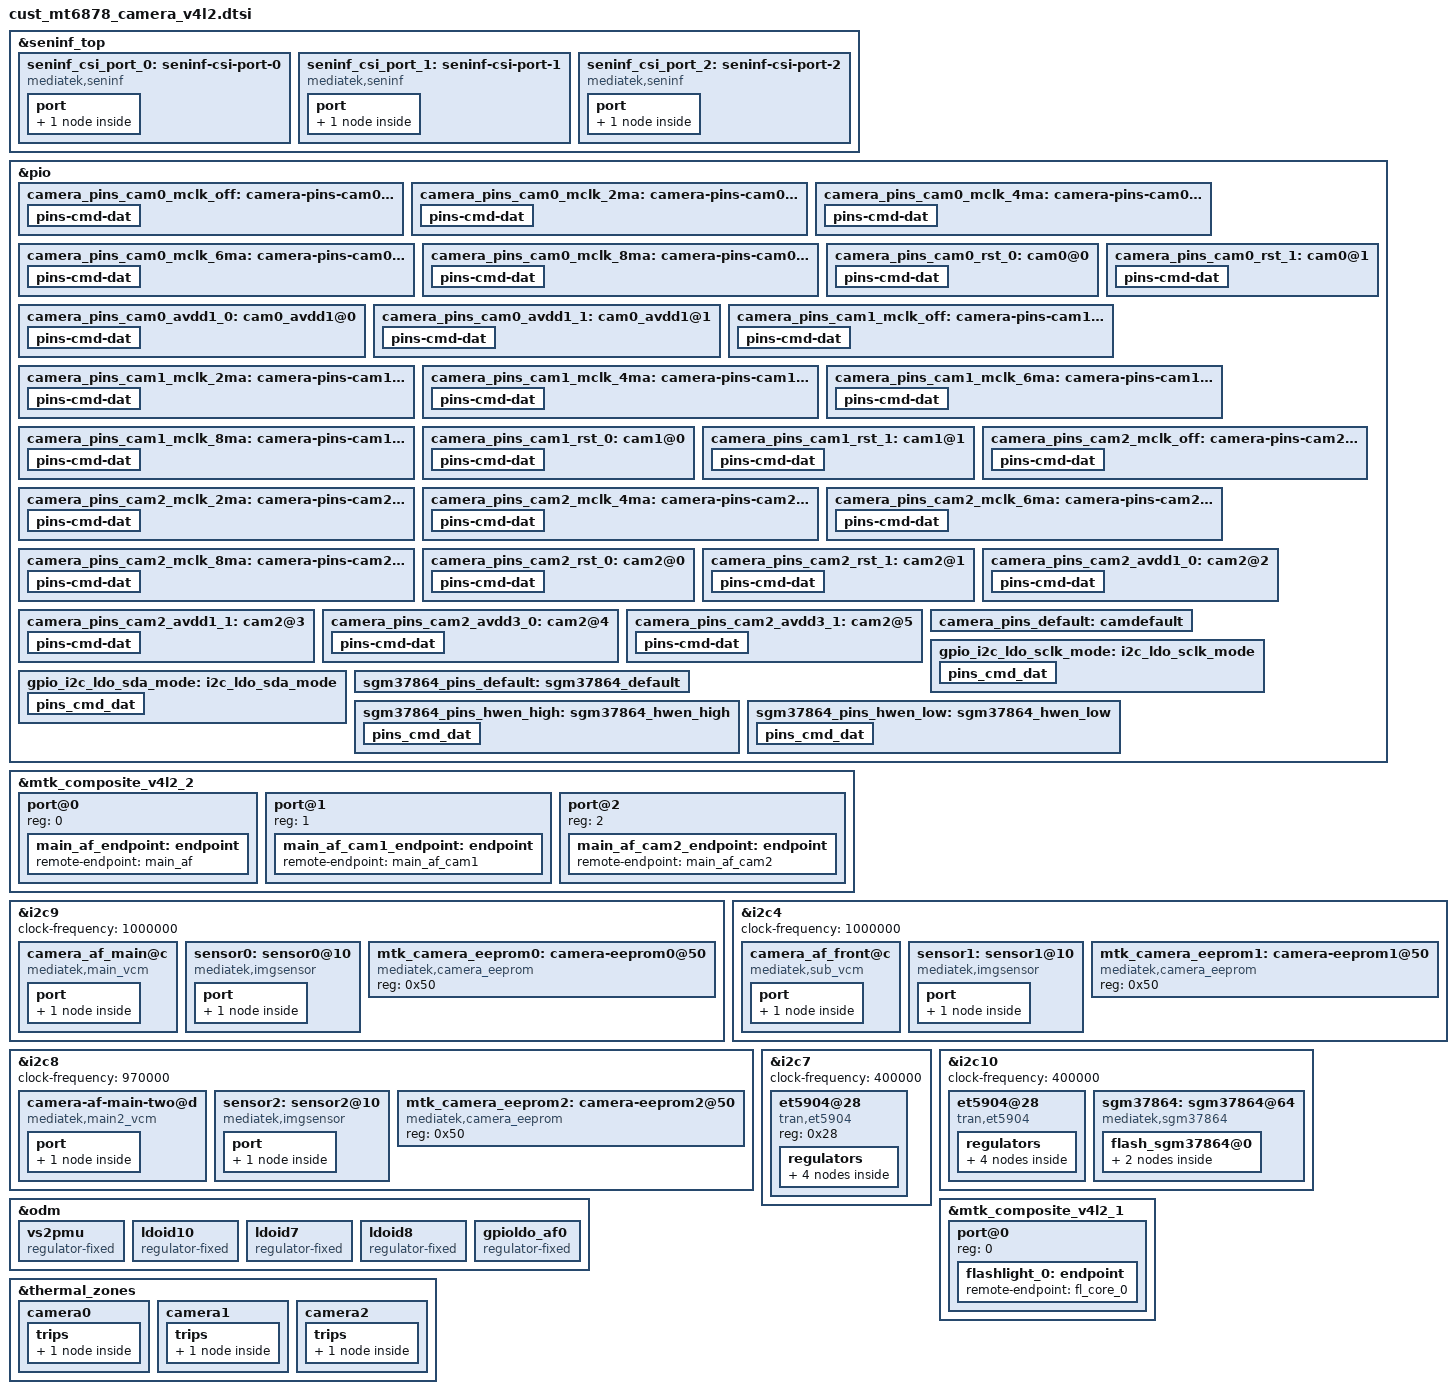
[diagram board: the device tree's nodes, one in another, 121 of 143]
// SPDX-License-Identifier: GPL-2.0
/* Copyright (c) 2020 MediaTek Inc. */
#include <dt-bindings/clock/mt6878-clk.h>

&seninf_top {
		seninf_csi_port_0: seninf-csi-port-0 {
			compatible = "mediatek,seninf";
			csi-port = "0";
			dphy-settle-delay-dt = <17>;
			nvmem-cells = <&csi_efuse0>;
			nvmem-cell-names = "rg_csi";
			port {
				seninf_csi_port_0_in: endpoint {
					remote-endpoint = <&sensor0_out>;
				};
			};
		};

		seninf_csi_port_1: seninf-csi-port-1 {
			compatible = "mediatek,seninf";
			csi-port = "1";
			hs-trail-parameter = <0x20>;
			nvmem-cells = <&csi_efuse1>;
			nvmem-cell-names = "rg_csi";
			port {
				seninf_csi_port_1_in: endpoint {
					remote-endpoint = <&sensor2_out>;
				};
			};
		};

		seninf_csi_port_2: seninf-csi-port-2 {
			compatible = "mediatek,seninf";
			csi-port = "2";
			hs-trail-parameter = <0x20>;
			nvmem-cells = <&csi_efuse2>;
			nvmem-cell-names = "rg_csi";
			port {
				seninf_csi_port_2_in: endpoint {
					remote-endpoint = <&sensor1_out>;
				};
			};
		};
};


/* CAMERA GPIO standardization */
&pio {
	camera_pins_cam0_mclk_off: camera-pins-cam0-mclk-off {
		pins-cmd-dat {
			pinmux = <PINMUX_GPIO93__FUNC_GPIO93>;
			drive-strength = <1>;
		};
	};
	camera_pins_cam0_mclk_2ma: camera-pins-cam0-mclk-2ma {
		pins-cmd-dat {
			pinmux = <PINMUX_GPIO93__FUNC_CMMCLK1>;
			drive-strength = <0>;
		};
	};
	camera_pins_cam0_mclk_4ma: camera-pins-cam0-mclk-4ma {
		pins-cmd-dat {
			pinmux = <PINMUX_GPIO93__FUNC_CMMCLK1>;
			drive-strength = <1>;
		};
	};
	camera_pins_cam0_mclk_6ma: camera-pins-cam0-mclk-6ma {
		pins-cmd-dat {
			pinmux = <PINMUX_GPIO93__FUNC_CMMCLK1>;
			drive-strength = <2>;
		};
	};
	camera_pins_cam0_mclk_8ma: camera-pins-cam0-mclk-8ma {
		pins-cmd-dat {
			pinmux = <PINMUX_GPIO93__FUNC_CMMCLK1>;
			drive-strength = <3>;
		};
	};
	camera_pins_cam0_rst_0: cam0@0 {
		pins-cmd-dat {
			pinmux = <PINMUX_GPIO25__FUNC_GPIO25>;
			slew-rate = <1>;
			output-low;
		};
	};
	camera_pins_cam0_rst_1: cam0@1 {
		pins-cmd-dat {
			pinmux = <PINMUX_GPIO25__FUNC_GPIO25>;
			slew-rate = <1>;
			output-high;
		};
	};

	camera_pins_cam0_avdd1_0: cam0_avdd1@0 {
		pins-cmd-dat {
			pinmux = <PINMUX_GPIO30__FUNC_GPIO30>;
			slew-rate = <1>;
			output-low;
		};
	};

	camera_pins_cam0_avdd1_1: cam0_avdd1@1 {
		pins-cmd-dat {
			pinmux = <PINMUX_GPIO30__FUNC_GPIO30>;
			slew-rate = <1>;
			output-high;
		};
	};

	camera_pins_cam1_mclk_off: camera-pins-cam1-mclk-off {
		pins-cmd-dat {
			pinmux = <PINMUX_GPIO96__FUNC_GPIO96>;
			drive-strength = <1>;
		};
	};
	camera_pins_cam1_mclk_2ma: camera-pins-cam1-mclk-2ma {
		pins-cmd-dat {
			pinmux = <PINMUX_GPIO96__FUNC_CMMCLK4>;
			drive-strength = <0>;
		};
	};
	camera_pins_cam1_mclk_4ma: camera-pins-cam1-mclk-4ma {
		pins-cmd-dat {
			pinmux = <PINMUX_GPIO96__FUNC_CMMCLK4>;
			drive-strength = <1>;
		};
	};
	camera_pins_cam1_mclk_6ma: camera-pins-cam1-mclk-6ma {
		pins-cmd-dat {
			pinmux = <PINMUX_GPIO96__FUNC_CMMCLK4>;
			drive-strength = <2>;
		};
	};
	camera_pins_cam1_mclk_8ma: camera-pins-cam1-mclk-8ma {
		pins-cmd-dat {
			pinmux = <PINMUX_GPIO96__FUNC_CMMCLK4>;
			drive-strength = <3>;
		};
	};
	camera_pins_cam1_rst_0: cam1@0 {
		pins-cmd-dat {
			pinmux = <PINMUX_GPIO24__FUNC_GPIO24>;
			slew-rate = <1>;
			output-low;
		};
	};
	camera_pins_cam1_rst_1: cam1@1 {
		pins-cmd-dat {
			pinmux = <PINMUX_GPIO24__FUNC_GPIO24>;
			slew-rate = <1>;
			output-high;
		};
	};
	camera_pins_cam2_mclk_off: camera-pins-cam2-mclk-off {
		pins-cmd-dat {
			pinmux = <PINMUX_GPIO94__FUNC_GPIO94>;
			drive-strength = <1>;
		};
	};
	camera_pins_cam2_mclk_2ma: camera-pins-cam2-mclk-2ma {
		pins-cmd-dat {
			pinmux = <PINMUX_GPIO94__FUNC_CMMCLK2>;
			drive-strength = <0>;
		};
	};
	camera_pins_cam2_mclk_4ma: camera-pins-cam2-mclk-4ma {
		pins-cmd-dat {
			pinmux = <PINMUX_GPIO94__FUNC_CMMCLK2>;
			drive-strength = <1>;
		};
	};
	camera_pins_cam2_mclk_6ma: camera-pins-cam2-mclk-6ma {
		pins-cmd-dat {
			pinmux = <PINMUX_GPIO94__FUNC_CMMCLK2>;
			drive-strength = <2>;
		};
	};
	camera_pins_cam2_mclk_8ma: camera-pins-cam2-mclk-8ma {
		pins-cmd-dat {
			pinmux = <PINMUX_GPIO94__FUNC_CMMCLK2>;
			drive-strength = <3>;
		};
	};
	camera_pins_cam2_rst_0: cam2@0 {
		pins-cmd-dat {
			pinmux = <PINMUX_GPIO26__FUNC_GPIO26>;
			slew-rate = <1>;
			output-low;
		};
	};
	camera_pins_cam2_rst_1: cam2@1 {
		pins-cmd-dat {
			pinmux = <PINMUX_GPIO26__FUNC_GPIO26>;
			slew-rate = <1>;
			output-high;
		};
	};
	camera_pins_cam2_avdd1_0: cam2@2 {
		pins-cmd-dat {
			pinmux = <PINMUX_GPIO120__FUNC_GPIO120>;
			slew-rate = <1>;
			output-low;
		};
	};

	camera_pins_cam2_avdd1_1: cam2@3 {
		pins-cmd-dat {
			pinmux = <PINMUX_GPIO120__FUNC_GPIO120>;
			slew-rate = <1>;
			output-high;
		};
	};

	camera_pins_cam2_avdd3_0: cam2@4 {
		pins-cmd-dat {
			pinmux = <PINMUX_GPIO134__FUNC_GPIO134>;
			slew-rate = <1>;
			output-low;
		};
	};
	camera_pins_cam2_avdd3_1: cam2@5 {
		pins-cmd-dat {
			pinmux = <PINMUX_GPIO134__FUNC_GPIO134>;
			slew-rate = <1>;
			output-high;
		};
	};

	camera_pins_default: camdefault {
	};
};
/* CAMERA GPIO end */

&mtk_composite_v4l2_2 {
	#address-cells = <1>;
	#size-cells = <0>;
	port@0 {
		reg = <0>;
		main_af_endpoint: endpoint {
			remote-endpoint = <&main_af>;
		};
	};
	port@1 {
		reg = <1>;
		main_af_cam1_endpoint: endpoint {
			remote-endpoint = <&main_af_cam1>;
		};
	};
	port@2 {
		reg = <2>;
		main_af_cam2_endpoint: endpoint {
			remote-endpoint = <&main_af_cam2>;
		};
	};
};

&i2c9 {
	status = "okay";
	clock-frequency = <1000000>;

	camera_af_main@c {
		compatible = "mediatek,main_vcm";
		reg = <0x0c>;
		vin-supply = <&gpioldo_af0>;
		port {
			main_af: endpoint {
				remote-endpoint = <&main_af_endpoint>;
			};
		};
	};

	sensor0: sensor0@10 {
		compatible = "mediatek,imgsensor";
		sensor-names = "imx896_mipi_raw";
		reg = <0x10>;
		#thermal-sensor-cells = <0>;
		sensor-matecodes = "imx896_17201919";
		pinctrl-names = "mclk_off",
				"mclk_2mA",
				"mclk_4mA",
				"mclk_6mA",
				"mclk_8mA",
				"rst_low",
				"rst_high",
				"avdd1_off",
				"avdd1_on";

		pinctrl-0 = <&camera_pins_cam0_mclk_off>;
		pinctrl-1 = <&camera_pins_cam0_mclk_2ma>;
		pinctrl-2 = <&camera_pins_cam0_mclk_4ma>;
		pinctrl-3 = <&camera_pins_cam0_mclk_6ma>;
		pinctrl-4 = <&camera_pins_cam0_mclk_8ma>;
		pinctrl-5 = <&camera_pins_cam0_rst_0>;
		pinctrl-6 = <&camera_pins_cam0_rst_1>;
		pinctrl-7 = <&camera_pins_cam0_avdd1_0>;
		pinctrl-8 = <&camera_pins_cam0_avdd1_1>;

		avdd-supply = <&ET5904LDO410>;
		dvdd-supply = <&ET5904LDO210>;
		dovdd-supply = <&mt6369_vant18>;

		clocks = <&topckgen_clk CLK_TOP_UVPLL192M_D32>,
			<&topckgen_clk CLK_TOP_UVPLL192M_D16>,
			<&topckgen_clk CLK_TOP_OSC_D20>,
			<&topckgen_clk CLK_TOP_UVPLL192M_D10>,
			<&topckgen_clk CLK_TOP_UVPLL192M_D8>,
			<&topckgen_clk CLK_TOP_TCK_26M_MX9>,
			<&topckgen_clk CLK_TOP_UNIVPLL_D6_D8>,
			<&topckgen_clk CLK_TOP_CAMTG2_SEL>;
		clock-names = "6", "12", "13", "19.2", "24", "26", "52", "mclk";


		status = "okay";
		port {
			sensor0_out: endpoint {
				remote-endpoint = <&seninf_csi_port_0_in>;
			};
		};
	};

	mtk_camera_eeprom0:camera-eeprom0@50 {
		compatible = "mediatek,camera_eeprom";
		reg = <0x50>;
		status = "okay";
	};
};

&i2c4 {
	status = "okay";
	clock-frequency = <1000000>;
	
	camera_af_front@c {
		compatible = "mediatek,sub_vcm";
		reg = <0x0c>;
		vin-supply = <&mt6369_vio28>;
		port {
			main_af_cam1: endpoint {
				remote-endpoint = <&main_af_cam1_endpoint>;
			};
		};
	};

	sensor1: sensor1@10 {
		compatible = "mediatek,imgsensor";
		sensor-names = "s5kjn1sub_mipi_raw";
		reg = <0x10>;
		sensor-matecodes = "s5kjn1sub_17201907";
		#thermal-sensor-cells = <0>;

		pinctrl-names = "mclk_off",
				"mclk_2mA",
				"mclk_4mA",
				"mclk_6mA",
				"mclk_8mA",
				"rst_low",
				"rst_high";
		pinctrl-0 = <&camera_pins_cam1_mclk_off>;
		pinctrl-1 = <&camera_pins_cam1_mclk_2ma>;
		pinctrl-2 = <&camera_pins_cam1_mclk_4ma>;
		pinctrl-3 = <&camera_pins_cam1_mclk_6ma>;
		pinctrl-4 = <&camera_pins_cam1_mclk_8ma>;
		pinctrl-5 = <&camera_pins_cam1_rst_0>;
		pinctrl-6 = <&camera_pins_cam1_rst_1>;

		avdd-supply = <&ET5904LDO310>;
		dvdd-supply = <&ET5904LDO110>;
		dovdd-supply = <&mt6369_vant18>;

		clocks = <&topckgen_clk CLK_TOP_UVPLL192M_D32>,
			<&topckgen_clk CLK_TOP_UVPLL192M_D16>,
			<&topckgen_clk CLK_TOP_OSC_D20>,
			<&topckgen_clk CLK_TOP_UVPLL192M_D10>,
			<&topckgen_clk CLK_TOP_UVPLL192M_D8>,
			<&topckgen_clk CLK_TOP_TCK_26M_MX9>,
			<&topckgen_clk CLK_TOP_UNIVPLL_D6_D8>,
			<&topckgen_clk CLK_TOP_CAMTG5_SEL>;
		clock-names = "6", "12", "13", "19.2", "24", "26", "52", "mclk";

		status = "okay";
		port {
			sensor1_out: endpoint {
				remote-endpoint = <&seninf_csi_port_2_in>;
			};
		};
	};

	mtk_camera_eeprom1:camera-eeprom1@50 {
		compatible = "mediatek,camera_eeprom";
		reg = <0x50>;
		status = "okay";
	};
};

&i2c8 {
	status = "okay";
	clock-frequency = <970000>;

	camera-af-main-two@d {
		compatible = "mediatek,main2_vcm";
		reg = <0x0d>;
		vin-supply = <&ET5904LDO47>;
		port {
			main_af_cam2: endpoint {
				remote-endpoint = <&main_af_cam2_endpoint>;
			};
		};
	};

	sensor2: sensor2@10 {
		compatible = "mediatek,imgsensor";
		sensor-names = "gc08a8wide_mipi_raw";
		reg = <0x10>;
		reindex-to = <0>;
		sensor-matecodes = "gc08a8wide_17201942";
		#cust-aov-csi-clk = <312>;
		#thermal-sensor-cells = <0>;

		pinctrl-names = "mclk_off",
				"mclk_2mA",
				"mclk_4mA",
				"mclk_6mA",
				"mclk_8mA",
				"rst_low",
				"rst_high";

		pinctrl-0 = <&camera_pins_cam2_mclk_off>;
		pinctrl-1 = <&camera_pins_cam2_mclk_2ma>;
		pinctrl-2 = <&camera_pins_cam2_mclk_4ma>;
		pinctrl-3 = <&camera_pins_cam2_mclk_6ma>;
		pinctrl-4 = <&camera_pins_cam2_mclk_8ma>;
		pinctrl-5 = <&camera_pins_cam2_rst_0>;
		pinctrl-6 = <&camera_pins_cam2_rst_1>;

		avdd-supply = <&ET5904LDO37>;
		dvdd-supply = <&ET5904LDO17>;
		dovdd-supply = <&mt6369_vant18>;

		clocks = <&topckgen_clk CLK_TOP_UVPLL192M_D32>,
			<&topckgen_clk CLK_TOP_UVPLL192M_D16>,
			<&topckgen_clk CLK_TOP_OSC_D20>,
			<&topckgen_clk CLK_TOP_UVPLL192M_D10>,
			<&topckgen_clk CLK_TOP_UVPLL192M_D8>,
			<&topckgen_clk CLK_TOP_TCK_26M_MX9>,
			<&topckgen_clk CLK_TOP_UNIVPLL_D6_D8>,
			<&topckgen_clk CLK_TOP_CAMTG3_SEL>;
		clock-names = "6", "12", "13", "19.2", "24", "26", "52", "mclk";


		status = "okay";
		port {
			sensor2_out: endpoint {
				remote-endpoint = <&seninf_csi_port_1_in>;
			};
		};
	};

	mtk_camera_eeprom2:camera-eeprom2@50 {
		compatible = "mediatek,camera_eeprom";
		reg = <0x50>;
		status = "okay";
	};
};

&pio {
	gpio_i2c_ldo_sclk_mode: i2c_ldo_sclk_mode {
		pins_cmd_dat {
			pinmux = <PINMUX_GPIO145__FUNC_SCL10>;
			drive-strength = <4>;
		};
	};

	gpio_i2c_ldo_sda_mode: i2c_ldo_sda_mode {
		pins_cmd_dat {
			pinmux = <PINMUX_GPIO146__FUNC_SDA10>;
			drive-strength = <3>;
		};
	};
};

&i2c7 {
    status = "okay";
    clock-frequency = <400000>;
    #address-cells = <1>;
    #size-cells = <0>;

    et5904@28 {
        compatible = "tran,et5904";
        reg = <0x28>;
        regulators {
            ET5904LDO17:ET5904LDO17 {
                regulator-name = "ET5904LDO17";
                regulator-min-microvolt = <600000>;
                regulator-max-microvolt = <1800000>;
            };
            ET5904LDO27:ET5904LDO27 {
                regulator-name = "ET5904LDO27";
                regulator-min-microvolt = <600000>;
                regulator-max-microvolt = <1800000>;
            };
            ET5904LDO37:ET5904LDO37 {
                regulator-name = "ET5904LDO37";
                regulator-min-microvolt = <1200000>;
                regulator-max-microvolt = <3300000>;
            };
            ET5904LDO47:ET5904LDO47 {
                regulator-name = "ET5904LDO47";
                regulator-min-microvolt = <1200000>;
                regulator-max-microvolt = <3300000>;
            };
        };
   };
};

&i2c10 {
        #address-cells = <1>;
        #size-cells = <0>;
	clock-frequency = <400000>;
	status = "okay";

        et5904@28 {
            compatible = "tran,et5904";
            pinctrl-names = "i2c_ldo_sclk_mode", "i2c_ldo_sda_mode";
            pinctrl-0 = <&gpio_i2c_ldo_sclk_mode>;
            pinctrl-1 = <&gpio_i2c_ldo_sda_mode>;
            reg = <0x28>;
            VIND-supply = <&vs2pmu>;
            regulators {
                ET5904LDO110:ET5904LDO110 {
                    regulator-name = "ET5904LDO110";
                    regulator-min-microvolt = <600000>;
                    regulator-max-microvolt = <1800000>;
                };
                ET5904LDO210:ET5904LDO210 {
                    regulator-name = "ET5904LDO210";
                    regulator-min-microvolt = <600000>;
                    regulator-max-microvolt = <1800000>;
                };
                ET5904LDO310:ET5904LDO310 {
                    regulator-name = "ET5904LDO310";
                    regulator-min-microvolt = <1200000>;
                    regulator-max-microvolt = <3300000>;
                };
                ET5904LDO410:ET5904LDO410 {
                    regulator-name = "ET5904LDO410";
                    regulator-min-microvolt = <1200000>;
                    regulator-max-microvolt = <3300000>;
                };
            };
       };
};

&odm {
    vs2pmu: vs2pmu {
      compatible = "regulator-fixed";
      regulator-name = "vs2pmu";
      regulator-min-microvolt = <1800000>;
      regulator-max-microvolt = <1800000>;
      gpio = <&pio 41 0x0>;
      enable-active-high;
      regulator-always-on;
      regulator-boot-on;
    };

    ldoid10: ldoid10 {
      compatible = "regulator-fixed";
      regulator-name = "ldoid10";
      regulator-min-microvolt = <1800000>;
      regulator-max-microvolt = <1800000>;
      gpio = <&pio 29 0x0>;
      enable-active-low;
      regulator-always-on;
      regulator-boot-on;
    };

    ldoid7: ldoid7 {
      compatible = "regulator-fixed";
      regulator-name = "ldoid7";
      regulator-min-microvolt = <1800000>;
      regulator-max-microvolt = <1800000>;
      gpio = <&pio 28 0x0>;
      enable-active-low;
      regulator-always-on;
      regulator-boot-on;
    };

    ldoid8: ldoid8 {
      compatible = "regulator-fixed";
      regulator-name = "ldoid8";
      regulator-min-microvolt = <1800000>;
      regulator-max-microvolt = <1800000>;
      gpio = <&pio 1 0x0>;
      enable-active-low;
      regulator-always-on;
      regulator-boot-on;
    };

    gpioldo_af0: gpioldo_af0 {
      compatible = "regulator-fixed";
      regulator-name = "gpioldo_af0";
      regulator-min-microvolt = <3300000>;
      regulator-max-microvolt = <3300000>;
      gpio = <&pio 57 0x0>;
      enable-active-high;
    };

};

&i2c10 {
	#address-cells = <1>;
	#size-cells = <0>;
	sgm37864:sgm37864@64 {
		compatible = "mediatek,sgm37864";
		reg = <0x64>;
		#cooling-cells = <2>;
		flashledno = <1>;
		pinctrl-names = "default", "hwen_high", "hwen_low";
		pinctrl-0 = <&sgm37864_pins_default>;
		pinctrl-1 = <&sgm37864_pins_hwen_high>;
		pinctrl-2 = <&sgm37864_pins_hwen_low>;
		status = "okay";
		flash_sgm37864@0{
			reg = <1>;
			type = <0>;
			ct = <0>;
			part = <0>;
			port@0 {
				fl_core_0: endpoint {
					remote-endpoint = <&flashlight_0>;
				};
			};
		};
	};
};

&pio {
	sgm37864_pins_default: sgm37864_default {
	};

	sgm37864_pins_hwen_high:sgm37864_hwen_high {
		pins_cmd_dat {
			pinmux = <PINMUX_GPIO153__FUNC_GPIO153>;
			slew-rate = <1>;
			output-high;
		};
	};

	sgm37864_pins_hwen_low: sgm37864_hwen_low {
		pins_cmd_dat {
			pinmux = <PINMUX_GPIO153__FUNC_GPIO153>;
			slew-rate = <1>;
			output-low;
		};
	};
};

&mtk_composite_v4l2_1 {
	#address-cells = <1>;
	#size-cells = <0>;
	port@0 {
		reg = <0>;
		flashlight_0: endpoint {
			remote-endpoint = <&fl_core_0>;
		};
	};
/*	port@1 {
		reg = <1>;
		flashlight_1: endpoint {
			remote-endpoint = <&fl_core_1>;
		};
	};*/
};

&thermal_zones {
	camera0: camera0 {
		polling-delay = <0>; /* milliseconds */
		polling-delay-passive = <0>; /* milliseconds */
		thermal-sensors = <&sensor0>;
		trips {
			camera0_crit: camera0-crit {
				temperature = <120000>;
				hysteresis = <2000>;
				type = "passive";
			};
		};
	};
	camera1: camera1 {
		polling-delay = <0>; /* milliseconds */
		polling-delay-passive = <0>; /* milliseconds */
		thermal-sensors = <&sensor1>;
		trips {
			camera1_crit: camera1-crit {
				temperature = <120000>;
				hysteresis = <2000>;
				type = "passive";
			};
		};
	};
	camera2: camera2 {
		polling-delay = <0>; /* milliseconds */
		polling-delay-passive = <0>; /* milliseconds */
		thermal-sensors = <&sensor2>;
		trips {
			camera2_crit: camera2-crit {
				temperature = <120000>;
				hysteresis = <2000>;
				type = "passive";
			};
		};
	};
};

